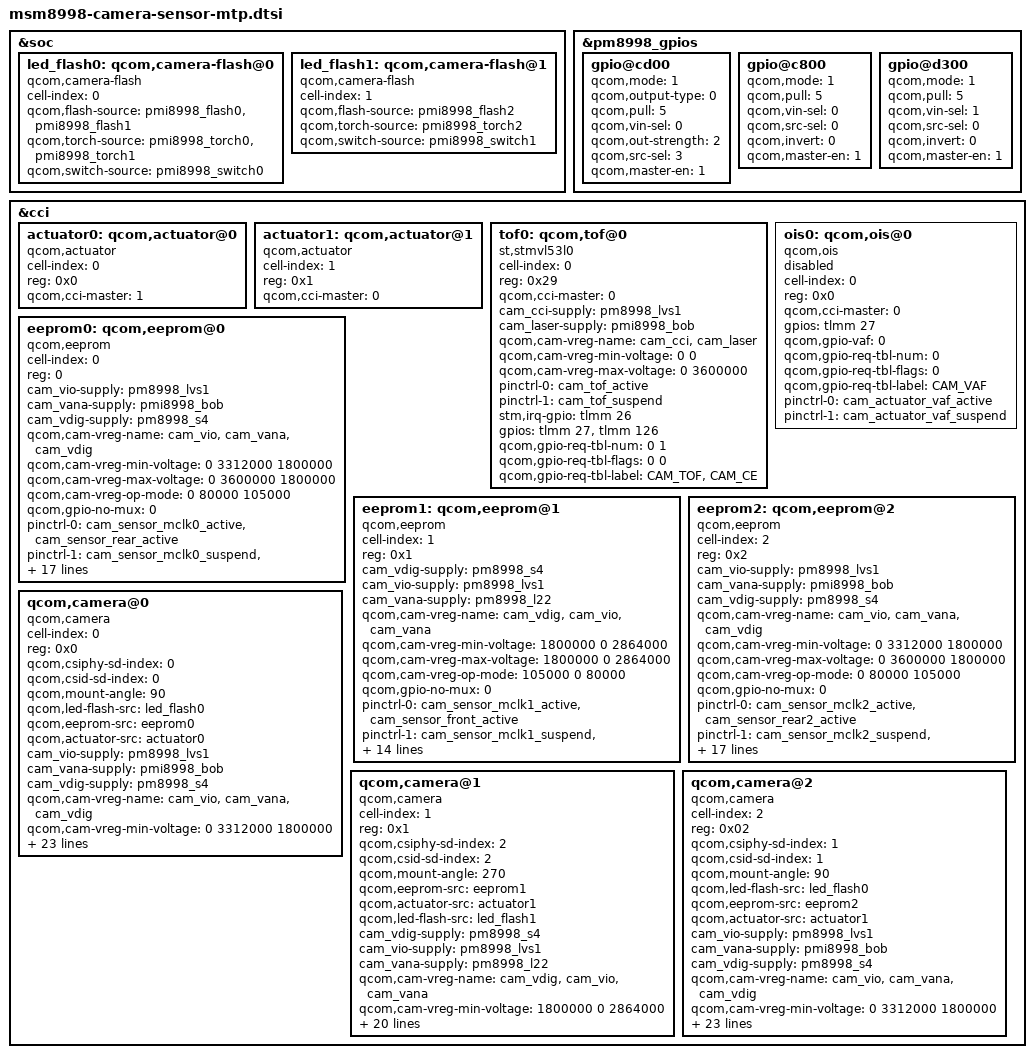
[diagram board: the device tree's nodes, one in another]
/*
 * Copyright (c) 2016-2017, The Linux Foundation. All rights reserved.
 *
 * This program is free software; you can redistribute it and/or modify
 * it under the terms of the GNU General Public License version 2 and
 * only version 2 as published by the Free Software Foundation.
 *
 * This program is distributed in the hope that it will be useful,
 * but WITHOUT ANY WARRANTY; without even the implied warranty of
 * MERCHANTABILITY or FITNESS FOR A PARTICULAR PURPOSE.  See the
 * GNU General Public License for more details.
 */

&soc {
	led_flash0: qcom,camera-flash@0 {
		cell-index = <0>;
		compatible = "qcom,camera-flash";
		qcom,flash-source = <&pmi8998_flash0 &pmi8998_flash1>;
		qcom,torch-source = <&pmi8998_torch0 &pmi8998_torch1>;
		qcom,switch-source = <&pmi8998_switch0>;
		status = "ok";
	};

	led_flash1: qcom,camera-flash@1 {
		cell-index = <1>;
		compatible = "qcom,camera-flash";
		qcom,flash-source = <&pmi8998_flash2>;
		qcom,torch-source = <&pmi8998_torch2>;
		qcom,switch-source = <&pmi8998_switch1>;
		status = "ok";
	};
};

&pm8998_gpios {
	gpio@cd00 { /* GPIO 14  for AL3200 MCLK 19.2MHz */
		qcom,mode = <1>;
		qcom,output-type = <0>;
		qcom,pull = <5>;
		qcom,vin-sel = <0>;
		qcom,out-strength = <2>;
		qcom,src-sel = <3>;
		qcom,master-en = <1>;
		status = "ok";
	};	
};

&cci {
	actuator0: qcom,actuator@0 {
		cell-index = <0>;
		reg = <0x0>;
		compatible = "qcom,actuator";
		qcom,cci-master = <1>;
	};

	actuator1: qcom,actuator@1 {
		cell-index = <1>;
		reg = <0x1>;
		compatible = "qcom,actuator";
		qcom,cci-master = <0>;
	};

	tof0:qcom,tof@0{
		cell-index = <0>;
		reg = <0x29>;
		compatible = "st,stmvl53l0";
		qcom,cci-master = <0>;
		cam_cci-supply = <&pm8998_lvs1>;
		cam_laser-supply = <&pmi8998_bob>;
		qcom,cam-vreg-name = "cam_cci", "cam_laser";
		qcom,cam-vreg-min-voltage = <0 0>;
		qcom,cam-vreg-max-voltage = <0 3600000>;
		pinctrl-names = "cam_default", "cam_suspend";
		pinctrl-0 = <&cam_tof_active>;
		pinctrl-1 = <&cam_tof_suspend>;
		stm,irq-gpio = <&tlmm 26 0x2008>;
		gpios = <&tlmm 27 0>, <&tlmm 126 0>;
		qcom,gpio-req-tbl-num = <0 1>;
		qcom,gpio-req-tbl-flags = <0 0>;
		qcom,gpio-req-tbl-label = "CAM_TOF", "CAM_CE";
	};

	ois0: qcom,ois@0 {
		cell-index = <0>;
		reg = <0x0>;
		compatible = "qcom,ois";
		qcom,cci-master = <0>;
		gpios = <&tlmm 27 0>;
		qcom,gpio-vaf = <0>;
		qcom,gpio-req-tbl-num = <0>;
		qcom,gpio-req-tbl-flags = <0>;
		qcom,gpio-req-tbl-label = "CAM_VAF";
		pinctrl-names = "cam_default", "cam_suspend";
		pinctrl-0 = <&cam_actuator_vaf_active>;
		pinctrl-1 = <&cam_actuator_vaf_suspend>;
		status = "disabled";
	};

	eeprom0: qcom,eeprom@0 {
		cell-index = <0>;
		reg = <0>;
		compatible = "qcom,eeprom";
		cam_vio-supply = <&pm8998_lvs1>;
		cam_vana-supply = <&pmi8998_bob>;
		cam_vdig-supply = <&pm8998_s4>;
		qcom,cam-vreg-name = "cam_vio", "cam_vana", "cam_vdig";
		qcom,cam-vreg-min-voltage = <0 3312000 1800000>;
		qcom,cam-vreg-max-voltage = <0 3600000 1800000>;
		qcom,cam-vreg-op-mode = <0 80000 105000>;
		qcom,gpio-no-mux = <0>;
		pinctrl-names = "cam_default", "cam_suspend";
		pinctrl-0 = <&cam_sensor_mclk0_active
				 &cam_sensor_rear_active>;
		pinctrl-1 = <&cam_sensor_mclk0_suspend
				 &cam_sensor_rear_suspend>;
		gpios = <&tlmm 13 0>,
			<&tlmm 30 0>,
			<&pm8998_gpios 20 0>,
			<&tlmm 27 0>,
			<&tlmm 8 0>;
		qcom,gpio-reset = <1>;
		qcom,gpio-vdig = <2>;
		qcom,gpio-vaf = <3>;
		qcom,gpio-vana = <4>;
		qcom,gpio-req-tbl-num = <0 1 2 3 4>;
		qcom,gpio-req-tbl-flags = <1 0 0 0 0>;
		qcom,gpio-req-tbl-label = "CAMIF_MCLK0",
					"CAM_RESET0",
					"CAM_VDIG0",
					"CAM_VAF",
					"CAM_VANA";
		qcom,sensor-position = <0>;
		qcom,sensor-mode = <0>;
		qcom,cci-master = <1>;
		status = "ok";
		clocks = <&clock_mmss clk_mclk0_clk_src>,
				<&clock_mmss clk_mmss_camss_mclk0_clk>;
		clock-names = "cam_src_clk", "cam_clk";
		qcom,clock-rates = <24000000 0>;
	};

	eeprom1: qcom,eeprom@1 {
		cell-index = <1>;
		reg = <0x1>;
		compatible = "qcom,eeprom";
		cam_vdig-supply = <&pm8998_s4>;
		cam_vio-supply = <&pm8998_lvs1>;
		cam_vana-supply = <&pm8998_l22>;
		qcom,cam-vreg-name = "cam_vdig", "cam_vio", "cam_vana";
		qcom,cam-vreg-min-voltage = <1800000 0 2864000>;
		qcom,cam-vreg-max-voltage = <1800000 0 2864000>;
		qcom,cam-vreg-op-mode = <105000 0 80000>;
		qcom,gpio-no-mux = <0>;
		pinctrl-names = "cam_default", "cam_suspend";
		pinctrl-0 = <&cam_sensor_mclk1_active
				 &cam_sensor_front_active>;
		pinctrl-1 = <&cam_sensor_mclk1_suspend
				 &cam_sensor_front_suspend>;
		gpios = <&tlmm 14 0>,
			<&tlmm 28 0>,
			<&pm8998_gpios 9 0>;
		qcom,gpio-reset = <1>;
		qcom,gpio-vdig = <2>;
		qcom,gpio-req-tbl-num = <0 1 2>;
		qcom,gpio-req-tbl-flags = <1 0 0>;
		qcom,gpio-req-tbl-label = "CAMIF_MCLK1",
					  "CAM_RESET1",
					  "CAM_VDIG1";
		qcom,sensor-position = <1>;
		qcom,sensor-mode = <0>;
		qcom,cci-master = <1>;
		status = "ok";
		clocks = <&clock_mmss clk_mclk1_clk_src>,
			<&clock_mmss clk_mmss_camss_mclk1_clk>;
		clock-names = "cam_src_clk", "cam_clk";
		qcom,clock-rates = <24000000 0>;
	};

	eeprom2: qcom,eeprom@2 {
		cell-index = <2>;
		reg = <0x2>;
		compatible = "qcom,eeprom";
		cam_vio-supply = <&pm8998_lvs1>;
		cam_vana-supply = <&pmi8998_bob>;
		cam_vdig-supply = <&pm8998_s4>;
		qcom,cam-vreg-name = "cam_vio", "cam_vana", "cam_vdig";
		qcom,cam-vreg-min-voltage = <0 3312000 1800000>;
		qcom,cam-vreg-max-voltage = <0 3600000 1800000>;
		qcom,cam-vreg-op-mode = <0 80000 105000>;
		qcom,gpio-no-mux = <0>;
		pinctrl-names = "cam_default", "cam_suspend";
		pinctrl-0 = <&cam_sensor_mclk2_active
				 &cam_sensor_rear2_active>;
		pinctrl-1 = <&cam_sensor_mclk2_suspend
				 &cam_sensor_rear2_suspend>;
		gpios = <&tlmm 15 0>,
			<&tlmm 9 0>,
			<&tlmm 29 0>,
			<&tlmm 27 0>,
			<&tlmm 8 0>;
		qcom,gpio-reset = <1>;
		qcom,gpio-vdig = <2>;
		qcom,gpio-vaf = <3>;
		qcom,gpio-vana = <4>;
		qcom,gpio-req-tbl-num = <0 1 2 3 4>;
		qcom,gpio-req-tbl-flags = <1 0 0 0 0>;
		qcom,gpio-req-tbl-label = "CAMIF_MCLK2",
					"CAM_RESET2",
					"CAM_VDIG2",
					"CAM_VAF",
					"CAM_VANA";
		qcom,sensor-position = <1>;
		qcom,sensor-mode = <0>;
		qcom,cci-master = <0>;
		status = "ok";
		clocks = <&clock_mmss clk_mclk1_clk_src>,
			<&clock_mmss clk_mmss_camss_mclk1_clk>;
		clock-names = "cam_src_clk", "cam_clk";
		qcom,clock-rates = <24000000 0>;
	};

	qcom,camera@0 {
		cell-index = <0>;
		compatible = "qcom,camera";
		reg = <0x0>;
		qcom,csiphy-sd-index = <0>;
		qcom,csid-sd-index = <0>;
		qcom,mount-angle = <90>;
		qcom,led-flash-src = <&led_flash0>;
		qcom,eeprom-src = <&eeprom0>;
		qcom,actuator-src = <&actuator0>;
		//cam-vaf-supply = <&pmi8998_bob>;
		cam_vio-supply = <&pm8998_lvs1>;
		cam_vana-supply = <&pmi8998_bob>;
		cam_vdig-supply = <&pm8998_s4>;
		qcom,cam-vreg-name = "cam_vio", "cam_vana", "cam_vdig";
		qcom,cam-vreg-min-voltage = <0 3312000 1800000>;
		qcom,cam-vreg-max-voltage = <0 3600000 1800000>;
		qcom,cam-vreg-op-mode = <0 80000 105000>;
		qcom,gpio-no-mux = <0>;
		pinctrl-names = "cam_default", "cam_suspend";
		pinctrl-0 = <&cam_sensor_mclk0_active
				 &cam_sensor_rear_active>;
		pinctrl-1 = <&cam_sensor_mclk0_suspend
				 &cam_sensor_rear_suspend>;
		gpios = <&tlmm 13 0>,
			<&tlmm 30 0>,
			<&pm8998_gpios 20 0>,
			<&tlmm 27 0>,
			<&tlmm 8 0>;
		qcom,gpio-reset = <1>;
		qcom,gpio-vdig = <2>;
		qcom,gpio-vaf = <3>;
		qcom,gpio-vana = <4>;
		qcom,gpio-req-tbl-num = <0 1 2 3 4>;
		qcom,gpio-req-tbl-flags = <1 0 0 0 0>;
		qcom,gpio-req-tbl-label = "CAMIF_MCLK0",
					"CAM_RESET0",
					"CAM_VDIG0",
					"CAM_VAF",
					"CAM_VANA";
		qcom,sensor-position = <0>;
		qcom,sensor-mode = <0>;
		qcom,cci-master = <1>;
		status = "ok";
		clocks = <&clock_mmss clk_mclk0_clk_src>,
				<&clock_mmss clk_mmss_camss_mclk0_clk>;
		clock-names = "cam_src_clk", "cam_clk";
		qcom,clock-rates = <24000000 0>;
	};

	qcom,camera@1 {
		cell-index = <1>;
		compatible = "qcom,camera";
		reg = <0x1>;
		qcom,csiphy-sd-index = <2>;
		qcom,csid-sd-index = <2>;
		qcom,mount-angle = <270>;
		qcom,eeprom-src = <&eeprom1>;
		qcom,actuator-src = <&actuator1>;

		qcom,led-flash-src = <&led_flash1>;
		cam_vdig-supply = <&pm8998_s4>;
		cam_vio-supply = <&pm8998_lvs1>;
		cam_vana-supply = <&pm8998_l22>;
		qcom,cam-vreg-name = "cam_vdig", "cam_vio", "cam_vana";
		qcom,cam-vreg-min-voltage = <1800000 0 2864000>;
		qcom,cam-vreg-max-voltage = <1800000 0 2864000>;
		qcom,cam-vreg-op-mode = <105000 0 80000>;
		qcom,gpio-no-mux = <0>;
		pinctrl-names = "cam_default", "cam_suspend";
		pinctrl-0 = <&cam_sensor_mclk1_active
				 &cam_sensor_front_active>;
		pinctrl-1 = <&cam_sensor_mclk1_suspend
				 &cam_sensor_front_suspend>;
		gpios = <&tlmm 14 0>,
			<&tlmm 28 0>,
			<&pm8998_gpios 9 0>;
		qcom,gpio-reset = <1>;
		qcom,gpio-vdig = <2>;
		qcom,gpio-req-tbl-num = <0 1 2>;
		qcom,gpio-req-tbl-flags = <1 0 0>;
		qcom,gpio-req-tbl-label = "CAMIF_MCLK1",
					  "CAM_RESET1",
					  "CAM_VDIG1";
		qcom,sensor-position = <1>;
		qcom,sensor-mode = <0>;
		qcom,cci-master = <1>;
		status = "ok";
		clocks = <&clock_mmss clk_mclk1_clk_src>,
			<&clock_mmss clk_mmss_camss_mclk1_clk>;
		clock-names = "cam_src_clk", "cam_clk";
		qcom,clock-rates = <24000000 0>;
	};

	qcom,camera@2 {
		cell-index = <2>;
		compatible = "qcom,camera";
		reg = <0x02>;
		qcom,csiphy-sd-index = <1>;
		qcom,csid-sd-index = <1>;
		qcom,mount-angle = <90>;
		qcom,led-flash-src = <&led_flash0>;
		qcom,eeprom-src = <&eeprom2>;
		qcom,actuator-src = <&actuator1>;
		//cam-vaf-supply = <&pmi8998_bob>;
		cam_vio-supply = <&pm8998_lvs1>;
		cam_vana-supply = <&pmi8998_bob>;
		cam_vdig-supply = <&pm8998_s4>;
		qcom,cam-vreg-name = "cam_vio", "cam_vana", "cam_vdig";
		qcom,cam-vreg-min-voltage = <0 3312000 1800000>;
		qcom,cam-vreg-max-voltage = <0 3600000 1800000>;
		qcom,cam-vreg-op-mode = <0 80000 105000>;
		qcom,gpio-no-mux = <0>;
		pinctrl-names = "cam_default", "cam_suspend";
		pinctrl-0 = <&cam_sensor_mclk2_active
				 &cam_sensor_rear2_active>;
		pinctrl-1 = <&cam_sensor_mclk2_suspend
				 &cam_sensor_rear2_suspend>;
		gpios = <&tlmm 15 0>,
			<&tlmm 9 0>,
			<&tlmm 29 0>,
			<&tlmm 27 0>,
			<&tlmm 8 0>;
		qcom,gpio-reset = <1>;
		qcom,gpio-vdig = <2>;
		qcom,gpio-vaf = <3>;
		qcom,gpio-vana = <4>;
		qcom,gpio-req-tbl-num = <0 1 2 3 4>;
		qcom,gpio-req-tbl-flags = <1 0 0 0 0>;
		qcom,gpio-req-tbl-label = "CAMIF_MCLK2",
					"CAM_RESET2",
					"CAM_VDIG2",
					"CAM_VAF",
					"CAM_VANA";
		qcom,sensor-position = <0>;
		qcom,sensor-mode = <2>;
		qcom,cci-master = <0>;
		status = "ok";
		clocks = <&clock_mmss clk_mclk2_clk_src>,
			<&clock_mmss clk_mmss_camss_mclk2_clk>;
		clock-names = "cam_src_clk", "cam_clk";
		qcom,clock-rates = <24000000 0>;
	};
};
&pm8998_gpios {
	gpio@c800 { /* GPIO 9 - CAMERA SENSOR 2 VDIG */
		qcom,mode = <1>;		/* Output */
		qcom,pull = <5>;		/* No Pull */
		qcom,vin-sel = <0>;		/* VIN1 GPIO_LV */
		qcom,src-sel = <0>;		/* GPIO */
		qcom,invert = <0>;		/* Invert */
		qcom,master-en = <1>;		/* Enable GPIO */
		status = "ok";
	};

	gpio@d300 { /* GPIO 20 - CAMERA SENSOR 0 VDIG */
		qcom,mode = <1>;		/* Output */
		qcom,pull = <5>;		/* No Pull */
		qcom,vin-sel = <1>;		/* VIN1 GPIO_MV */
		qcom,src-sel = <0>;		/* GPIO */
		qcom,invert = <0>;		/* Invert */
		qcom,master-en = <1>;		/* Enable GPIO */
		status = "ok";
	};
};
